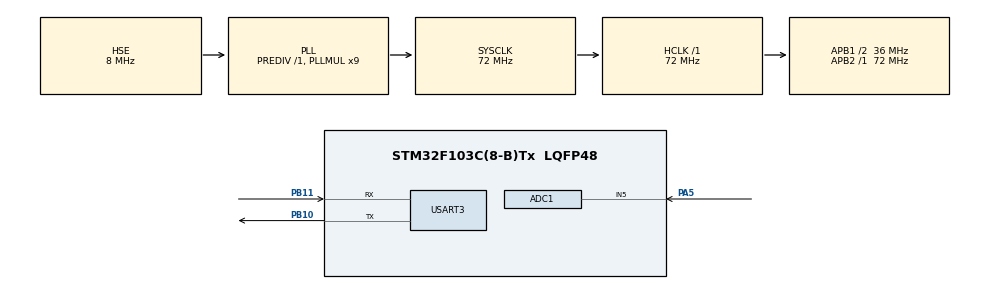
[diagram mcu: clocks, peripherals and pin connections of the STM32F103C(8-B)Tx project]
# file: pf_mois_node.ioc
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ADC1.Channel-0\#ChannelRegularConversion=ADC_CHANNEL_5
ADC1.ContinuousConvMode=ENABLE
ADC1.NbrOfConversionFlag=1
ADC1.Rank-0\#ChannelRegularConversion=1
ADC1.SamplingTime-0\#ChannelRegularConversion=ADC_SAMPLETIME_71CYCLES_5
ADC1.master=1
Dma.ADC1.0.Direction=DMA_PERIPH_TO_MEMORY
Dma.ADC1.0.Instance=DMA1_Channel1
Dma.ADC1.0.MemDataAlignment=DMA_MDATAALIGN_HALFWORD
Dma.ADC1.0.MemInc=DMA_MINC_DISABLE
Dma.ADC1.0.Mode=DMA_CIRCULAR
Dma.ADC1.0.PeriphDataAlignment=DMA_PDATAALIGN_HALFWORD
Dma.ADC1.0.PeriphInc=DMA_PINC_DISABLE
Dma.ADC1.0.Priority=DMA_PRIORITY_LOW
Dma.Request0=ADC1
Mcu.Family=STM32F1
Mcu.Name=STM32F103C(8-B)Tx
Mcu.Package=LQFP48
NVIC.DMA1_Channel1_IRQn=true\:0\:0\:false\:false\:true\:false\:true
NVIC.PriorityGroup=NVIC_PRIORITYGROUP_4
PA13.Mode=JTAG_4_pins
PA13.Signal=SYS_JTMS-SWDIO
PA14.Mode=JTAG_4_pins
PA14.Signal=SYS_JTCK-SWCLK
PA15.Mode=JTAG_4_pins
PA15.Signal=SYS_JTDI
PA5.Signal=ADCx_IN5
PB10.Mode=Asynchronous
PB10.Signal=USART3_TX
PB11.Mode=Asynchronous
PB11.Signal=USART3_RX
PB3.Mode=JTAG_4_pins
PB3.Signal=SYS_JTDO-TRACESWO
PD0-OSC_IN.Mode=HSE-External-Oscillator
PD0-OSC_IN.Signal=RCC_OSC_IN
PD1-OSC_OUT.Mode=HSE-External-Oscillator
PD1-OSC_OUT.Signal=RCC_OSC_OUT
ProjectManager.HeapSize=0x200
ProjectManager.StackSize=0x400
ProjectManager.TargetToolchain=MDK-ARM V5.27
RCC.ADCPresc=RCC_ADCPCLK2_DIV6
RCC.AHBFreq_Value=72000000
RCC.APB1CLKDivider=RCC_HCLK_DIV2
RCC.APB1Freq_Value=36000000
RCC.APB1TimFreq_Value=72000000
RCC.APB2Freq_Value=72000000
RCC.APB2TimFreq_Value=72000000
RCC.HCLKFreq_Value=72000000
RCC.PLLMUL=RCC_PLL_MUL9
RCC.PLLSourceVirtual=RCC_PLLSOURCE_HSE
RCC.SYSCLKFreq_VALUE=72000000
RCC.SYSCLKSource=RCC_SYSCLKSOURCE_PLLCLK
RCC.USBFreq_Value=72000000
SH.ADCx_IN5.0=ADC1_IN5,IN5
USART3.VirtualMode=VM_ASYNC
board=custom

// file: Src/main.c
/* USER CODE BEGIN Header */
/**
  ******************************************************************************
  * @file           : main.c
  * @brief          : Main program body
  ******************************************************************************
  * @attention
  *
  * <h2><center>&copy; Copyright (c) 2020 STMicroelectronics.
  * All rights reserved.</center></h2>
  *
  * This software component is licensed by ST under BSD 3-Clause license,
  * the "License"; You may not use this file except in compliance with the
  * License. You may obtain a copy of the License at:
  *                        opensource.org/licenses/BSD-3-Clause
  *
  ******************************************************************************
  */
/* USER CODE END Header */

#include "main.h"
#include "adc.h"
#include "dma.h"
#include "usart.h"
#include "gpio.h"

/* USER CODE BEGIN Includes */
#include "stdio.h"

/* USER CODE END Includes */

/* USER CODE BEGIN PV */
uint32_t rawmois;
char buf[16];
float room_hum = 40; // qt=40 normal=50
float room_val = 3350;
float water_val = 1650;

/* USER CODE END PV */

void SystemClock_Config(void);

int main(void)
{

  /* MCU Configuration--------------------------------------------------------*/

  /* Reset of all peripherals, Initializes the Flash interface and the Systick. */
  HAL_Init();

  /* Configure the system clock */
  SystemClock_Config();

  /* Initialize all configured peripherals */
  MX_GPIO_Init();
  MX_DMA_Init();
  MX_ADC1_Init();
  MX_USART3_UART_Init();
  /* USER CODE BEGIN 2 */
	HAL_ADC_Start_DMA(&hadc1, &rawmois, 1);

  /* USER CODE END 2 */

  /* Infinite loop */
  /* USER CODE BEGIN WHILE */
  while (1)
  {// qt=85 normal=90
		float moisRH = ((room_hum - 85) / (room_val - water_val)) * rawmois + room_hum - (room_val * (room_hum - 85)) / (room_val - water_val);
		sprintf(buf, "AT+DATA=%.2f\r", moisRH);
		HAL_UART_Transmit(&huart3, (uint8_t *)buf, 16, 10);
		HAL_Delay(15000);
    /* USER CODE END WHILE */

  }
}

void SystemClock_Config(void)
{
  RCC_OscInitTypeDef RCC_OscInitStruct = {0};
  RCC_ClkInitTypeDef RCC_ClkInitStruct = {0};
  RCC_PeriphCLKInitTypeDef PeriphClkInit = {0};

  /** Initializes the CPU, AHB and APB busses clocks
  */
  RCC_OscInitStruct.OscillatorType = RCC_OSCILLATORTYPE_HSE;
  RCC_OscInitStruct.HSEState = RCC_HSE_ON;
  RCC_OscInitStruct.HSEPredivValue = RCC_HSE_PREDIV_DIV1;
  RCC_OscInitStruct.HSIState = RCC_HSI_ON;
  RCC_OscInitStruct.PLL.PLLState = RCC_PLL_ON;
  RCC_OscInitStruct.PLL.PLLSource = RCC_PLLSOURCE_HSE;
  RCC_OscInitStruct.PLL.PLLMUL = RCC_PLL_MUL9;
  if (HAL_RCC_OscConfig(&RCC_OscInitStruct) != HAL_OK)
  {
    Error_Handler();
  }
  /** Initializes the CPU, AHB and APB busses clocks
  */
  RCC_ClkInitStruct.ClockType = RCC_CLOCKTYPE_HCLK|RCC_CLOCKTYPE_SYSCLK
                              |RCC_CLOCKTYPE_PCLK1|RCC_CLOCKTYPE_PCLK2;
  RCC_ClkInitStruct.SYSCLKSource = RCC_SYSCLKSOURCE_PLLCLK;
  RCC_ClkInitStruct.AHBCLKDivider = RCC_SYSCLK_DIV1;
  RCC_ClkInitStruct.APB1CLKDivider = RCC_HCLK_DIV2;
  RCC_ClkInitStruct.APB2CLKDivider = RCC_HCLK_DIV1;

  if (HAL_RCC_ClockConfig(&RCC_ClkInitStruct, FLASH_LATENCY_2) != HAL_OK)
  {
    Error_Handler();
  }
  PeriphClkInit.PeriphClockSelection = RCC_PERIPHCLK_ADC;
  PeriphClkInit.AdcClockSelection = RCC_ADCPCLK2_DIV6;
  if (HAL_RCCEx_PeriphCLKConfig(&PeriphClkInit) != HAL_OK)
  {
    Error_Handler();
  }
}

void Error_Handler(void)
{
}

/************************ (C) COPYRIGHT STMicroelectronics *****END OF FILE****/
